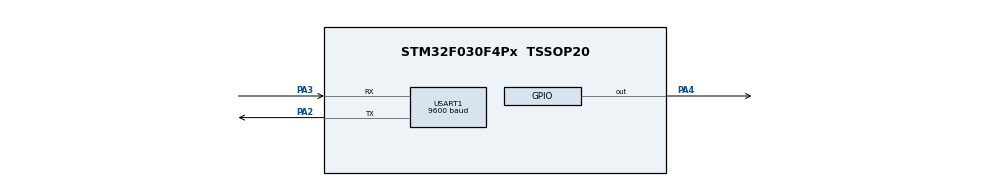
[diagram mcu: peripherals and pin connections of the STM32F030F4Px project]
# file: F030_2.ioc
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Mcu.Family=STM32F0
Mcu.Name=STM32F030F4Px
Mcu.Package=TSSOP20
PA2.Mode=Asynchronous
PA2.Signal=USART1_TX
PA3.Mode=Asynchronous
PA3.Signal=USART1_RX
PA4.Signal=GPIO_Output
PF0-OSC_IN.Mode=HSE-External-Oscillator
PF0-OSC_IN.Signal=RCC_OSC_IN
PF1-OSC_OUT.Mode=HSE-External-Oscillator
PF1-OSC_OUT.Signal=RCC_OSC_OUT
ProjectManager.HeapSize=0x200
ProjectManager.StackSize=0x400
ProjectManager.TargetToolchain=STM32CubeIDE
USART1.BaudRate=9600
USART1.VirtualMode-Asynchronous=VM_ASYNC
board=custom

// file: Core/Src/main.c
/* USER CODE BEGIN Header */
/**
  ******************************************************************************
  * @file           : main.c
  * @brief          : Main program body
  ******************************************************************************
  * @attention
  *
  * Copyright (c) 2023 STMicroelectronics.
  * All rights reserved.
  *
  * This software is licensed under terms that can be found in the LICENSE file
  * in the root directory of this software component.
  * If no LICENSE file comes with this software, it is provided AS-IS.
  *
  ******************************************************************************
  */
/* USER CODE END Header */
#include "main.h"
#include "stdio.h"

UART_HandleTypeDef huart1;

/* USER CODE BEGIN PV */
short num;
/* USER CODE END PV */

void SystemClock_Config(void);
static void MX_GPIO_Init(void);
static void MX_USART1_UART_Init(void);

int main(void)
{

  /* MCU Configuration--------------------------------------------------------*/

  /* Reset of all peripherals, Initializes the Flash interface and the Systick. */
  HAL_Init();

  /* Configure the system clock */
  SystemClock_Config();

  /* Initialize all configured peripherals */
  MX_GPIO_Init();
  MX_USART1_UART_Init();

  /* Infinite loop */
  /* USER CODE BEGIN WHILE */
  while (1)
  {
  HAL_Delay(100);
  HAL_GPIO_TogglePin(GPIOA, GPIO_PIN_5);
  num++;
  //num=powf(num,2);
  //printf("Hello %s  %d \r\n", "worlddd", num);
  //printf("Hello11 %s  %d \r\n", "world", num);
    /* USER CODE END WHILE */

  }
}

void SystemClock_Config(void)
{
  RCC_OscInitTypeDef RCC_OscInitStruct = {0};
  RCC_ClkInitTypeDef RCC_ClkInitStruct = {0};
  RCC_PeriphCLKInitTypeDef PeriphClkInit = {0};

  /** Initializes the RCC Oscillators according to the specified parameters
  * in the RCC_OscInitTypeDef structure.
  */
  RCC_OscInitStruct.OscillatorType = RCC_OSCILLATORTYPE_HSI;
  RCC_OscInitStruct.HSIState = RCC_HSI_ON;
  RCC_OscInitStruct.HSICalibrationValue = RCC_HSICALIBRATION_DEFAULT;
  RCC_OscInitStruct.PLL.PLLState = RCC_PLL_NONE;
  if (HAL_RCC_OscConfig(&RCC_OscInitStruct) != HAL_OK)
  {
    Error_Handler();
  }

  /** Initializes the CPU, AHB and APB buses clocks
  */
  RCC_ClkInitStruct.ClockType = RCC_CLOCKTYPE_HCLK|RCC_CLOCKTYPE_SYSCLK
                              |RCC_CLOCKTYPE_PCLK1;
  RCC_ClkInitStruct.SYSCLKSource = RCC_SYSCLKSOURCE_HSI;
  RCC_ClkInitStruct.AHBCLKDivider = RCC_SYSCLK_DIV1;
  RCC_ClkInitStruct.APB1CLKDivider = RCC_HCLK_DIV1;

  if (HAL_RCC_ClockConfig(&RCC_ClkInitStruct, FLASH_LATENCY_0) != HAL_OK)
  {
    Error_Handler();
  }
  PeriphClkInit.PeriphClockSelection = RCC_PERIPHCLK_USART1;
  PeriphClkInit.Usart1ClockSelection = RCC_USART1CLKSOURCE_PCLK1;
  if (HAL_RCCEx_PeriphCLKConfig(&PeriphClkInit) != HAL_OK)
  {
    Error_Handler();
  }
}

static void MX_USART1_UART_Init(void)
{

  huart1.Instance = USART1;
  huart1.Init.BaudRate = 9600;
  huart1.Init.WordLength = UART_WORDLENGTH_8B;
  huart1.Init.StopBits = UART_STOPBITS_1;
  huart1.Init.Parity = UART_PARITY_NONE;
  huart1.Init.Mode = UART_MODE_TX_RX;
  huart1.Init.HwFlowCtl = UART_HWCONTROL_NONE;
  huart1.Init.OverSampling = UART_OVERSAMPLING_16;
  huart1.Init.OneBitSampling = UART_ONE_BIT_SAMPLE_DISABLE;
  huart1.AdvancedInit.AdvFeatureInit = UART_ADVFEATURE_NO_INIT;
  if (HAL_UART_Init(&huart1) != HAL_OK)
  {
    Error_Handler();
  }

}

static void MX_GPIO_Init(void)
{
  GPIO_InitTypeDef GPIO_InitStruct = {0};

  /* GPIO Ports Clock Enable */
  __HAL_RCC_GPIOF_CLK_ENABLE();
  __HAL_RCC_GPIOA_CLK_ENABLE();

  /*Configure GPIO pin Output Level */
  HAL_GPIO_WritePin(GPIOA, GPIO_PIN_4, GPIO_PIN_RESET);

  /*Configure GPIO pin : PA4 */
  GPIO_InitStruct.Pin = GPIO_PIN_4;
  GPIO_InitStruct.Mode = GPIO_MODE_OUTPUT_PP;
  GPIO_InitStruct.Pull = GPIO_NOPULL;
  GPIO_InitStruct.Speed = GPIO_SPEED_FREQ_LOW;
  HAL_GPIO_Init(GPIOA, &GPIO_InitStruct);

}

/* USER CODE BEGIN 4 */
int _write(int fd, char* ptr, int len) {
    HAL_UART_Transmit(&huart1, (uint8_t *) ptr, len, HAL_MAX_DELAY);
    return len;
}
/* USER CODE END 4 */

void Error_Handler(void)
{
  __disable_irq();
  while (1)
  {
  }
}
